# CC1312PSIP register map
File version: 1.0
CPU: CM4 1.0, other endian, MPU, FPU, 3 interrupt priority bits
Registers are 32-bit, read-write, reset 0x0 unless marked. A register's access mark holds for its fields unless they carry their own. Offsets are from the block's base; [hi:lo] are bit positions; {n}, {i} and the like mark numbered series.

## GPIO — MCU GPIO - I/F for controlling and reading IO status and IO event status
Base 0x40022000
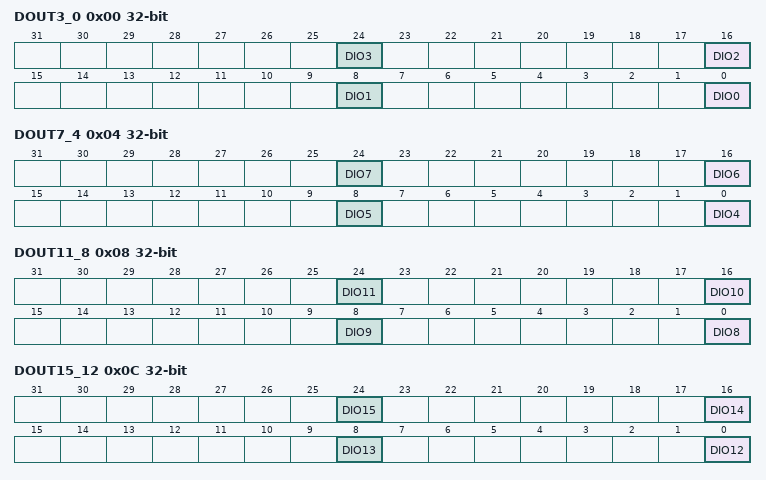
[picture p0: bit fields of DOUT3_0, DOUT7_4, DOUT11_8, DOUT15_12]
0x00 DOUT3_0 — Data Out 0 to 3 Alias register for byte access to each bit in DOUT31_0
  [8n] DIO{n} wo (n=0..3) — [{8n}:{8n}] Sets the state of the pin that is configured as DIO#{n}, if the corresponding DOE31_0 bitfield is set.
0x04 DOUT7_4 — Data Out 4 to 7 Alias register for byte access to each bit in DOUT31_0
  [8n-32] DIO{n} wo (n=4..7) — [{8n-32}:{8n-32}] Sets the state of the pin that is configured as DIO#{n}, if the corresponding DOE31_0 bitfield is set.
0x08 DOUT11_8 — Data Out 8 to 11 Alias register for byte access to each bit in DOUT31_0
  [8n-64] DIO{n} wo (n=8..11) — [{8n-64}:{8n-64}] Sets the state of the pin that is configured as DIO#{n}, if the corresponding DOE31_0 bitfield is set.
0x0C DOUT15_12 — Data Out 12 to 15 Alias register for byte access to each bit in DOUT31_0
  [8n-96] DIO{n} wo (n=12..15) — [{8n-96}:{8n-96}] Sets the state of the pin that is configured as DIO#{n}, if the corresponding DOE31_0 bitfield is set.
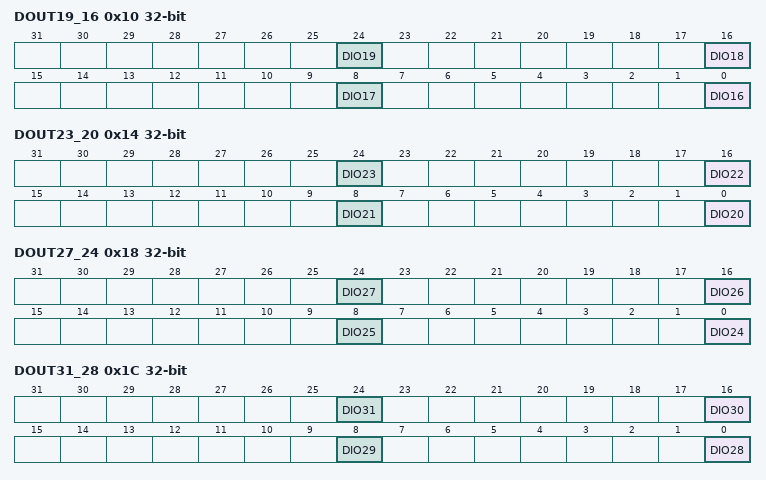
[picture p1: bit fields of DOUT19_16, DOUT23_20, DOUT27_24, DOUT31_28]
0x10 DOUT19_16 — Data Out 16 to 19 Alias register for byte access to each bit in DOUT31_0
  [8n-128] DIO{n} wo (n=16..19) — [{8n-128}:{8n-128}] Sets the state of the pin that is configured as DIO#{n}, if the corresponding DOE31_0 bitfield is set.
0x14 DOUT23_20 — Data Out 20 to 23 Alias register for byte access to each bit in DOUT31_0
  [8n-160] DIO{n} wo (n=20..23) — [{8n-160}:{8n-160}] Sets the state of the pin that is configured as DIO#{n}, if the corresponding DOE31_0 bitfield is set.
0x18 DOUT27_24 — Data Out 24 to 27 Alias register for byte access to each bit in DOUT31_0
  [8n-192] DIO{n} wo (n=24..27) — [{8n-192}:{8n-192}] Sets the state of the pin that is configured as DIO#{n}, if the corresponding DOE31_0 bitfield is set.
0x1C DOUT31_28 — Data Out 28 to 31 Alias register for byte access to each bit in DOUT31_0
  [8n-224] DIO{n} wo (n=28..31) — [{8n-224}:{8n-224}] Sets the state of the pin that is configured as DIO#{n}, if the corresponding DOE31_0 bitfield is set.
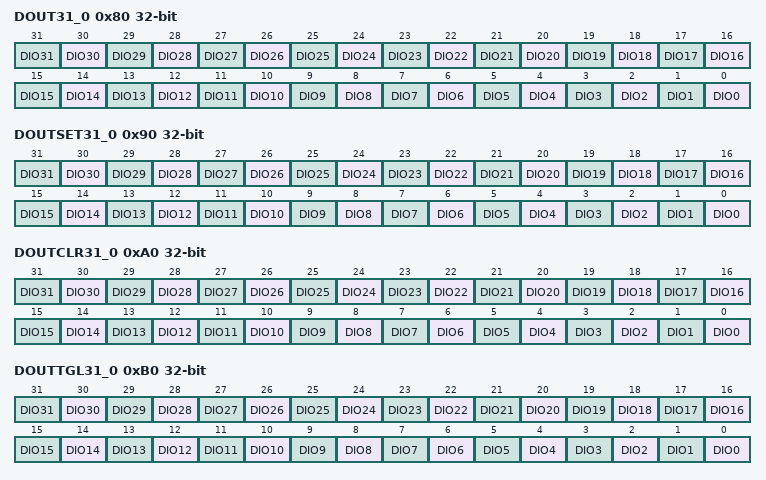
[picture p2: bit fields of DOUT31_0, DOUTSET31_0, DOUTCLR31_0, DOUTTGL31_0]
0x80 DOUT31_0 — Data Output for DIO 0 to 31
  [n] DIO{n} (n=0..31) — [{n}:{n}] Data output for DIO {n}
0x90 DOUTSET31_0 — Data Out Set Writing 1 to a bit position sets the corresponding bit in the DOUT31_0 register
  [n] DIO{n} wo (n=0..31) — [{n}:{n}] Set bit {n}
0xA0 DOUTCLR31_0 — Data Out Clear Writing 1 to a bit position clears the corresponding bit in the DOUT31_0 register
  [n] DIO{n} wo (n=0..31) — [{n}:{n}] Clears bit {n}
0xB0 DOUTTGL31_0 — Data Out Toggle Writing 1 to a bit position will invert the corresponding DIO output.
  [n] DIO{n} (n=0..31) — [{n}:{n}] Toggles bit {n}
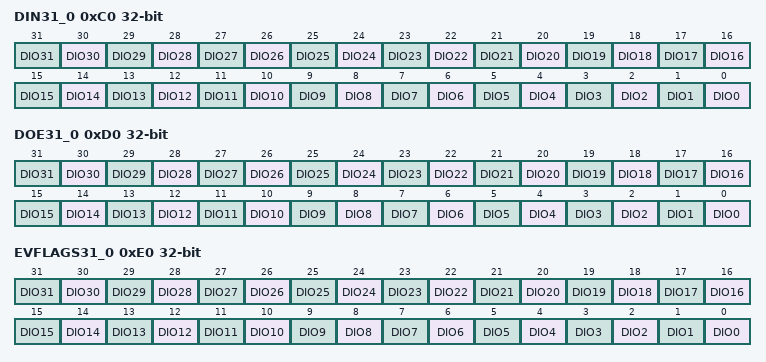
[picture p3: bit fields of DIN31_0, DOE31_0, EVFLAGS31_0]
0xC0 DIN31_0 — Data Input from DIO 0 to 31
  [n] DIO{n} ro (n=0..31) — [{n}:{n}] Data input from DIO {n}
0xD0 DOE31_0 — Data Output Enable for DIO 0 to 31
  [n] DIO{n} (n=0..31) — [{n}:{n}] Data output enable for DIO {n}
0xE0 EVFLAGS31_0 — Event Register for DIO 0 to 31 Reading this registers will return 1 for triggered event and 0 for non-triggered events. Writing a 1 to a bit field will clear the event. The configuration of events is done inside MCU IOC, e.g. events for DIO #0 is configured in IOC:IOCFG0.EDGE_DET and IOC:IOCFG0.EDGE_IRQ_EN.
  [n] DIO{n} (n=0..31) — [{n}:{n}] Event for DIO {n}

## PKA_INT — Integrated module which includes the PKA K
Base 0x40027000
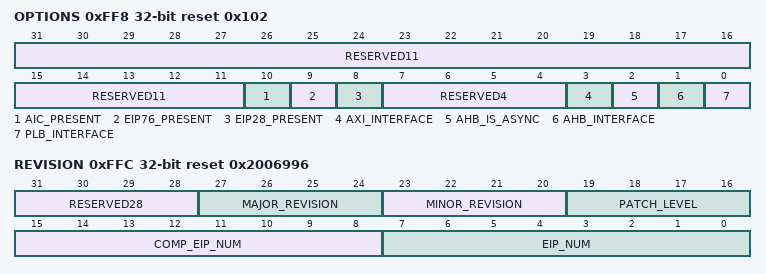
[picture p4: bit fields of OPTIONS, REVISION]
0xFF8 OPTIONS reset 0x102 — PKA Options register
  [31:11] RESERVED11 ro — [31:11] Ignore on read
  [10] AIC_PRESENT ro — [10:10] When set to '1', indicates that an EIP201 AIC is included in the EIP150
  [9] EIP76_PRESENT ro — [9:9] When set to '1', indicates that the EIP76 TRNG is included in the EIP150
  [8] EIP28_PRESENT ro — [8:8] When set to '1', indicates that the EIP28 PKA is included in the EIP150
  [7:4] RESERVED4 ro — [7:4] Ignore on read
  [3] AXI_INTERFACE ro — [3:3] When set to '1', indicates that the EIP150 is equipped with a AXI interface
  [2] AHB_IS_ASYNC ro — [2:2] When set to '1', indicates that AHB interface is asynchronous Only applicable when AHB_INTERFACE is 1
  [1] AHB_INTERFACE — [1:1] When set to '1', indicates that the EIP150 is equipped with a AHB interface
  [0] PLB_INTERFACE — [0:0] When set to '1', indicates that the EIP150 is equipped with a PLB interface
0xFFC REVISION reset 0x2006996 — PKA hardware revision register This register allows the host access to the hardware revision number of the PKA engine for software driver matching and diagnostic purposes. It is always located at the highest address in the access space of the module and contains an encoding of the EIP number (with its complement as signature) for recognition of the hardware module.
  [31:28] RESERVED28 ro — [31:28] These bits should be ignored on read
  [27:24] MAJOR_REVISION ro — [27:24] These bits encode the major version number for this module
  [23:20] MINOR_REVISION ro — [23:20] These bits encode the minor version number for this module
  [19:16] PATCH_LEVEL ro — [19:16] These bits encode the hardware patch level for this module they start at value 0 on the first release
  [15:8] COMP_EIP_NUM ro — [15:8] These bits simply contain the complement of bits [7:0], used by a driver to ascertain that the EIP150 revision register is indeed read
  [7:0] EIP_NUM ro — [7:0] These bits encode the AuthenTec EIP number for the EIP150
